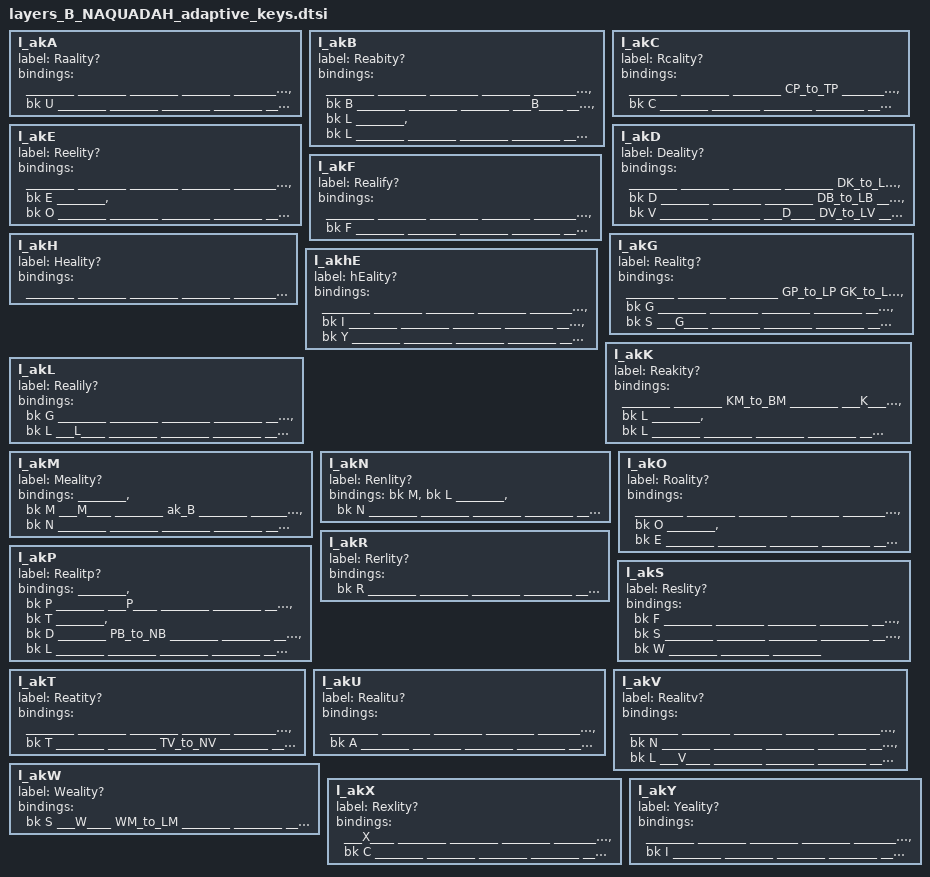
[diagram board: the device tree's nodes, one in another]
                l_akA {
                        label = "Raality?";
                        bindings = <
________   ________   ________   ________   ________          ________   ________   &bk U      ________   ________
________   ________   ________   ________   ________          ________   ___A____   ________   ________   ________
________   ________   ________   ________   ________          ________   ________   ________   ________   ________
                        ________   ________   ________      ________   ________   ________
                        >;
                };


                l_akB {
                        label = "Reabity?";
                        bindings = <
________   ________   ________   ________   ________          ________   ________   ________   ________   ________
&bk B      ________   ________   ________   ___B____          ________   ________   ________   ________   ________
________   &bk L      ________   &bk L      ________          ________   ________   ________   ________   ________
//         ^-- For M -> B(k) -> L
                        ________   ________   ________      ________   ________   ________
                        >;
                };


                l_akC {
                        label = "Rcality?";
                        bindings = <
________   ________   ________   CP_to_TP   ________          ________   ________   ________   ________   ________
___C____   ________   ________   ________   ________          ________   ________   ________   ________   ________
________   &bk C      ________   ________   ________          ________   ________   ________   ________   ________
                        ________   ________   ________      ________   ________   ________
                        >;
                };


                l_akD {
                        label = "Deality?";
                        bindings = <
________   ________   ________   ________   DK_to_LK          ________   ________   ________   ________   ________
&bk D      ________   ________   ________   DB_to_LB          ________   ________   ________   ________   ________
&bk V      ________   ________   ___D____   DV_to_LV          ________   ________   ________   ________   ________
                        ________   ________   ________      ________   ________   ________
                        >;
                };


                l_akE {
                        label = "Reelity?";
                        bindings = <
________   ________   ________   ________   ________          ________   &bk E      ________   &bk O      ________
________   ________   ________   ________   ________          ________   ________   ___E____   ________   ________
________   ________   ________   ________   ________          ________   ________   ________   ________   ________
                        ________   ________   ________      ________   ________   ________
                        >;
                };


                l_akF {
                        label = "Realify?";
                        bindings = <
________   ________   ________   ________   ________          ________   ________   ________   ________   ________
________   ________   ________   ________   ________          ________   ________   ________   ________   ________
___F____   &bk F      ________   ________   ________          ________   ________   ________   ________   ________
                        ________   ________   ________      ________   ________   ________
                        >;
                };


                l_akG {
                        label = "Realitg?";
                        bindings = <
________   ________   ________   GP_to_LP   GK_to_LK          ________   ________   ________   ________   ________
&bk G      ________   ________   ________   ________          ________   ________   ________   ________   ________
&bk S      ___G____   ________   ________   ________          ________   ________   ________   ________   ________
                        ________   ________   ________      ________   ________   ________
                        >;
                };


                l_akH {
                        label = "Heality?";
                        bindings = <
________   ________   ________   ________   ________          ________   ________   ________   ________   ________
________   ________   ________   ________   ________          ________   ________   ak_hE      ________   ___H____
________   ________   ________   ________   ________          ________   ________   ________   ________   ________
                        ________   ________   ________      ________   ________   ________
                        >;
                };


                l_akhE {
                        label = "hEality?";
                        bindings = <
________   ________   ________   ________   ________          ________   &bk I      ________   ________   ________
________   ________   ________   ________   ________          ________   ________   __hE____   ________   ________
________   ________   ________   ________   ________          ________   &bk Y      ________   ________   ________
                        ________   ________   ________      ________   ________   ________
                        >;
                };


                l_akK {
                        label = "Reakity?";
                        bindings = <
________   ________   KM_to_BM   ________   ___K____          ________   ________   ________   ________   ________
________   ________   ________   ________   ________          ________   ________   ________   ________   ________
________   &bk L      ________   &bk L      ________          ________   ________   ________   ________   ________
                        ________   ________   ________      ________   ________   ________
                        >;
                };


                l_akL {
                        label = "Realily?";
                        bindings = <
&bk G      ________   ________   ________   ________          ________   ________   ________   ________   ________
________   ________   ________   ________   ________          ________   ________   ________   ________   ________
________   &bk L      ___L____   ________   ________          ________   ________   ________   ________   ________
                        ________   ________   ________      ________   ________   ________
                        >;
                };


                l_akM {
                        label = "Meality?";
                        bindings = <
//                                          v-- For M -> B(k) -> L
________   &bk M      ___M____   ________   ak_B              ________   ________   ________   ________   ________
________   ________   ________   &bk N      ________          ________   ________   ________   ________   ________
________   ________   ________   ________   ________          ________   ________   ________   ________   ________
                        ________   ________   ________      ________   ________   ________
                        >;
                };


                l_akN {
                        label = "Renlity?";
                        bindings = <
&bk M      &bk L      ________   &bk N      ________           ________   ________   ________   ________   ________
________   ________   ___N____   ________   ________           ________   ________   ________   ________   ________
________   ________   ________   ________   ________           ________   ________   ________   ________   ________
                        ________   ________   ________      ________   ________   ________
                        >;
                };


                l_akO {
                        label = "Roality?";
                        bindings = <
________   ________   ________   ________   ________          ________   &bk O      ________   &bk E      ________
________   ________   ________   ________   ________          ________   ________   ________   ________   ________
________   ________   ________   ________   ________          ________   ________   ___O____   ________   ________
                        ________   ________   ________      ________   ________   ________
                        >;
                };


                l_akP {
                        label = "Realitp?";
                        bindings = <
________   &bk P      ________   ___P____   ________          ________   ________   ________   ________   ________
&bk T      ________   &bk D      ________   PB_to_NB          ________   ________   ________   ________   ________
________   &bk L      ________   ________   ________          ________   ________   ________   ________   ________
//         ^-- For M->P->L, but also for regular P->L
                        ________   ________   ________      ________   ________   ________
                        >;
                };


                l_akR {
                        label = "Rerlity?";
                        bindings = <
&bk R      ________   ________   ________   ________          ________   ________   ________   ________   ________
________   ________   ________   ________   ________          ________   ________   ________   ________   ________
________   ________   ________   ________   ________          ________   ________   ________   ________   ________
                        ________   ________   ___R____      ________   ________   ________
                        >;
                };


                l_akS {
                        label = "Reslity?";
                        bindings = <
&bk F      ________   ________   ________   ________          ________   ________   ________   ________   ________
________   ___S____   ________   ________   ________          ________   ________   ________   ________   ________
________   ________   ________   &bk S      ________          ________   ________   ________   ________   ________
                        ________   ________   &bk W         ________   ________   ________
                        >;
                };


                l_akT {
                        label = "Reatity?";
                        bindings = <
________   ________   ________   ________   ________          ________   ________   ________   ________   ________
________   ________   ________   ___T____   ________          ________   ________   ________   ________   ________
________   &bk T      ________   ________   TV_to_NV          ________   ________   ________   ________   ________
                        ________   ________   ________      ________   ________   ________
                        >;
                };


                l_akU {
                        label = "Realitu?";
                        bindings = <
________   ________   ________   ________   ________          ________   ________   &bk A      ________   ________
________   ________   ________   ________   ________          ________   ________   ________   ________   ________
________   ________   ________   ________   ________          ________   ___U____   ________   ________   ________
                        ________   ________   ________      ________   ________   ________
                        >;
                };


                l_akV {
                        label = "Realitv?";
                        bindings = <
________   ________   ________   ________   ________          ________   ________   ________   ________   ________
________   ________   ________   &bk N      ________          ________   ________   ________   ________   ________
________   ________   ________   &bk L      ___V____          ________   ________   ________   ________   ________
                        ________   ________   ________      ________   ________   ________
                        >;
                };


                l_akW {
                        label = "Weality?";
                        bindings = <
&bk S      ___W____   WM_to_LM   ________   ________          ________   ________   ________   ________   ________
________   ________   ________   ________   ________          ________   ________   ________   ________   ________
________   ________   ________   ________   ________          ________   ________   ________   ________   ________
                        ________   ________   ________      ________   ________   ________
                        >;
                };


                l_akX {
                        label = "Rexlity?";
                        bindings = <
___X____   ________   ________   ________   ________          ________   ________   ________   ________   ________
________   &bk C      ________   ________   ________          ________   ________   ________   ________   ________
________   ________   ________   ________   ________          ________   ________   ________   ________   ________
                        ________   ________   ________      ________   ________   ________
                        >;
                };


                l_akY {
                        label = "Yeality?";
                        bindings = <
________   ________   ________   ________   ________          ________   ________   ________   ________   ________
________   ________   ________   ________   ________          ________   ________   ________   ________   &bk I
________   ________   ________   ________   ________          ________   ________   ________   ___Y____   ________
                        ________   ________   ________      ________   ________   ________
                        >;
                };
